# LCD_E_1 register map
Vendor: Texas Instruments
Peripheral module from a debugger description file (folder msp430).
Registers are 16-bit, access not given, no defined reset value unless marked. A register's access mark holds for its fields unless they carry their own. Offsets are as the file gives them; lines under a group give offsets from that group; [hi:lo] are bit positions; {n}, {i} and the like mark numbered series; 'fields as' and 'values as' point back to an identical list; <NAME> marks a mode.

## LCD_E
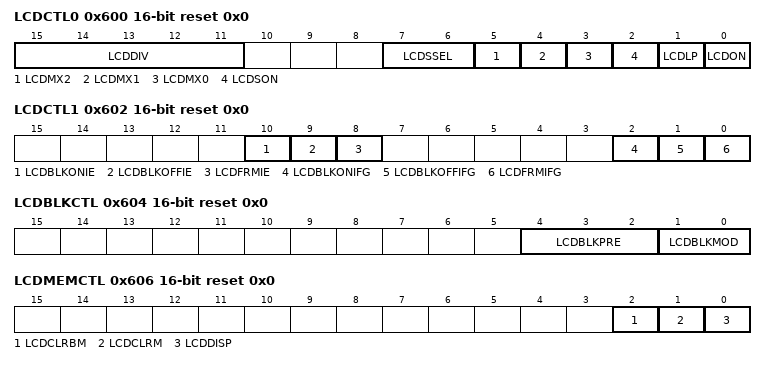
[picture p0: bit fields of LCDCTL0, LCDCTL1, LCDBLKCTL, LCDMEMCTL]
0x600 LCDCTL0 rw reset 0x0 — LCD_E Control Register 0
  [15:11] LCDDIV — LCD_E LCD frequency divider Bit: 0
    {v}=LCD_E LCD frequency divider: /{v+1} (v=0..31)
  [7:6] LCDSSEL — LCD_E Clock Select Bit: 0
    {v}=LCD_E Clock Select: {v} (v=0..3)
  [5] LCDMX2 — LCD_E Mux Rate Bit: 2
  [4] LCDMX1 — LCD_E Mux Rate Bit: 1
  [3] LCDMX0 — LCD_E Mux Rate Bit: 0
  [2] LCDSON — LCD_E LCD Segments On
  [1] LCDLP — LCD_E Low Power Waveform
  [0] LCDON — LCD_E LCD On
0x602 LCDCTL1 rw reset 0x0 — LCD_E Control Register 1
  [10] LCDBLKONIE — LCD_E LCD blinking on interrupt flag
  [9] LCDBLKOFFIE — LCD_E LCD blinking off interrupt flag
  [8] LCDFRMIE — LCD_E LCD frame interrupt enable
  [2] LCDBLKONIFG — LCD_E LCD blinking on interrupt flag
  [1] LCDBLKOFFIFG — LCD_E LCD blinking off interrupt flag
  [0] LCDFRMIFG — LCD_E LCD frame interrupt flag
0x604 LCDBLKCTL rw reset 0x0 — LCD_E blinking control register
  [4:2] LCDBLKPRE — LCD_E Clock pre-scaler for blinking frequency Bit: 0
    {v}=LCD_E Clock pre-scaler for blinking frequency: {v} (v=0..7)
  [1:0] LCDBLKMOD — LCD_E Blinking mode Bit: 0
    0=LCD_E Blinking mode: Off; 1=LCD_E Blinking mode: Individual; 2=LCD_E Blinking mode: All; 3=LCD_E Blinking mode: Switching
0x606 LCDMEMCTL rw reset 0x0 — LCD_E memory control register
  [2] LCDCLRBM — LCD_E Clear LCD blinking memory
  [1] LCDCLRM — LCD_E Clear LCD memory
  [0] LCDDISP — LCD_E LCD memory registers for display
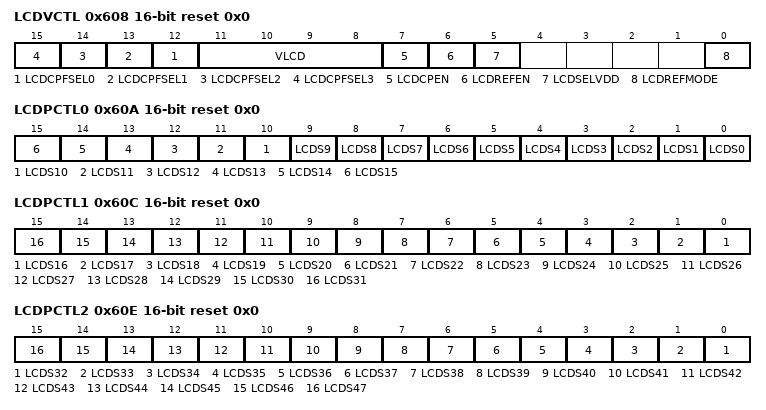
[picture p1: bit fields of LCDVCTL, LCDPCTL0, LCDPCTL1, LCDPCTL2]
0x608 LCDVCTL rw reset 0x0 — LCD_E Voltage Control Register
  [n+12] LCDCPFSEL{n} (n=0..3) — Charge pump frequency selection Bit: {n}
  [11:8] VLCD — VLCD select: 0
    0=VLCD = 2.60V; 1=VLCD = 2.66V; 2=VLCD = 2.72V; 3=VLCD = 2.78V; 4=VLCD = 2.84V; 5=VLCD = 2.90V; 6=VLCD = 2.96V; 7=VLCD = 3.02V; 8=VLCD = 3.08V; 9=VLCD = 3.14V; 10=VLCD = 3.20V; 11=VLCD = 3.26V; 12=VLCD = 3.32V; 13=VLCD = 3.38V; 14=VLCD = 3.44V; 15=VLCD = 3.50V
  [7] LCDCPEN — Charge pump enable
  [6] LCDREFEN — Internal reference voltage enable on R13
  [5] LCDSELVDD — selects if R33 is supplied either from Vcc internally or from charge pump
  [0] LCDREFMODE — Selects wether R13 voltage is switched or in static mode
0x60A LCDPCTL0 rw reset 0x0 — LCD_E Port Control Register 0
  [n] LCDS{n} (n=0..15) — LCD Segment {n} enable.
0x60C LCDPCTL1 rw reset 0x0 — LCD_E Port Control Register 1
  [n-16] LCDS{n} (n=16..31) — LCD Segment {n} enable.
0x60E LCDPCTL2 rw reset 0x0 — LCD_E Port Control Register 2
  [n-32] LCDS{n} (n=32..47) — LCD Segment {n} enable.
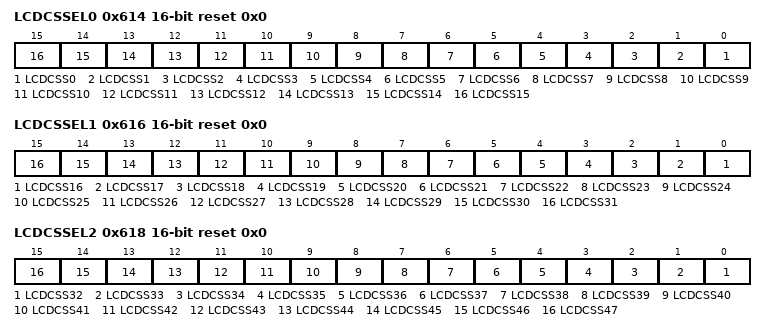
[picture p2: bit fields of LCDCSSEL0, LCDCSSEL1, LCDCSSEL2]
0x614 LCDCSSEL0 rw reset 0x0 — LCD_E COM/SEG select register 0
  [n] LCDCSS{n} (n=0..15) — Selects pin L{n} as either common or segment line
0x616 LCDCSSEL1 rw reset 0x0 — LCD_E COM/SEG select register 1
  [n-16] LCDCSS{n} (n=16..31) — Selects pin L{n} as either common or segment line
0x618 LCDCSSEL2 rw reset 0x0 — LCD_E COM/SEG select register 2
  [n-32] LCDCSS{n} (n=32..47) — Selects pin L{n} as either common or segment line
0x61E LCDIV — LCD_E Interrupt Vector Register
0x620 LCDM0W — LCD Memory 0/1
0x622 LCDM2W — LCD Memory 2/3
0x624 LCDM4W — LCD Memory 4/5
0x626 LCDM6W — LCD Memory 6/7
0x628 LCDM8W — LCD Memory 8/9
0x62A LCDM10W — LCD Memory 10/11
0x62C LCDM12W — LCD Memory 12/13
0x62E LCDM14W — LCD Memory 14/15
0x630 LCDM16W — LCD Memory 16/17
0x632 LCDM18W — LCD Memory 18/19
0x634 LCDM20W — LCD Memory 20/21
0x636 LCDM22W — LCD Memory 22/23
0x638 LCDM24W — LCD Memory 24/25
0x63A LCDM26W — LCD Memory 26/27
0x63C LCDM28W — LCD Memory 28/29
0x63E LCDM30W — LCD Memory 30/31
0x640 LCDM32W — LCD Memory 32/33
0x640 LCDBM0W — LCD Blinking Memory 0/1
0x642 LCDM34W — LCD Memory 34/35
0x642 LCDBM2W — LCD Blinking Memory 2/3
0x644 LCDM36W — LCD Memory 36/37
0x644 LCDBM4W — LCD Blinking Memory 4/5
0x646 LCDM38W — LCD Memory 38/39
0x646 LCDBM6W — LCD Blinking Memory 6/7
0x648 LCDBM8W — LCD Blinking Memory 8/9
0x64A LCDBM10W — LCD Blinking Memory 10/11
0x64C LCDBM12W — LCD Blinking Memory 12/13
0x64E LCDBM14W — LCD Blinking Memory 14/15
0x650 LCDBM16W — LCD Blinking Memory 16/17
0x652 LCDBM18W — LCD Blinking Memory 18/19
